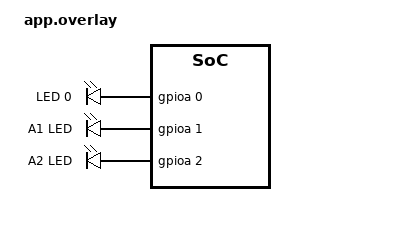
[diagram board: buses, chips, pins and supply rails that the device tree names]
/* SPDX-License-Identifier: Apache-2.0 */

/ {
	aliases {
		led0 = &led0;
		led1 = &led1;
		led2 = &led2;
	};

	leds {
		compatible = "gpio-leds";

		led0: led_0 {
			gpios = <&gpioa 0 GPIO_ACTIVE_HIGH>;
			label = "LED 0";
		};

		led1: led_1 {
			gpios = <&gpioa 1 GPIO_ACTIVE_HIGH>;
			label = "A1 LED";
		};

		led2: led_2 {
			gpios = <&gpioa 2 GPIO_ACTIVE_HIGH>;
			label = "A2 LED";
		};
	};
};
